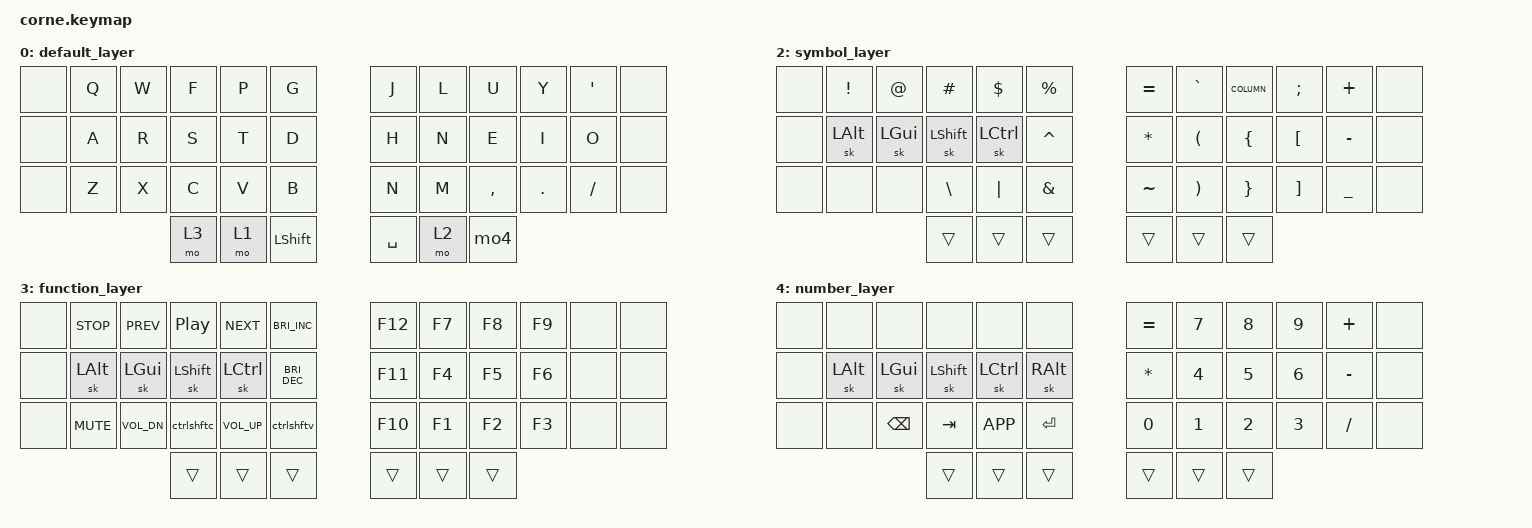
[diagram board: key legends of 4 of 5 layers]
/*
 * Seniply Layout
 * https://stevep99.github.io/seniply/
 */

#include <behaviors.dtsi>
#include <dt-bindings/zmk/keys.h>
#include <dt-bindings/zmk/bt.h>

/ {

    macros {
        bk: bk {
            label = "Backward";
            compatible = "zmk,behavior-macro";
            #binding-cells = <0>;
            bindings
                = <&macro_press &kp LALT>
                , <&macro_tap &kp LEFT>
                , <&macro_release &kp LALT>
                ;
        };
        fw: fw {
            label = "Forward";
            compatible = "zmk,behavior-macro";
            #binding-cells = <0>;
            bindings
                = <&macro_press &kp LALT>
                , <&macro_tap &kp RIGHT>
                , <&macro_release &kp LALT>
                ;
        };
        fnd: fnd {
            label = "Forward";
            compatible = "zmk,behavior-macro";
            #binding-cells = <0>;
            bindings
                = <&macro_press &kp LCTRL>
                , <&macro_tap &kp F>
                , <&macro_release &kp LCTRL>
                ;
        };  
        ctrlz: ctrlz {
            label = "Forward";
            compatible = "zmk,behavior-macro";
            #binding-cells = <0>;
            bindings
                = <&macro_press &kp LCTRL>
                , <&macro_tap &kp Z>
                , <&macro_release &kp LCTRL>
                ;
        };  
        ctrlx: ctrlx {
            label = "Forward";
            compatible = "zmk,behavior-macro";
            #binding-cells = <0>;
            bindings
                = <&macro_press &kp LCTRL>
                , <&macro_tap &kp X>
                , <&macro_release &kp LCTRL>
                ;
        };  
        ctrlc: ctrlc {
            label = "Forward";
            compatible = "zmk,behavior-macro";
            #binding-cells = <0>;
            bindings
                = <&macro_press &kp LCTRL>
                , <&macro_tap &kp C>
                , <&macro_release &kp LCTRL>
                ;
        };   
        ctrlv: ctrlv {
            label = "Forward";
            compatible = "zmk,behavior-macro";
            #binding-cells = <0>;
            bindings
                = <&macro_press &kp LCTRL>
                , <&macro_tap &kp V>
                , <&macro_release &kp LCTRL>
                ;
        };                                               
        ctrlshftc: ctrlshftc {
            label = "Forward";
            compatible = "zmk,behavior-macro";
            #binding-cells = <0>;
            bindings
                = <&macro_press &kp LCTRL>
                , <&macro_press &kp LSHFT>
                , <&macro_tap &kp C>
                , <&macro_release &kp LSHFT>
                , <&macro_release &kp LCTRL>
                ;
        };   
        ctrlshftv: ctrlshftv {
            label = "Forward";
            compatible = "zmk,behavior-macro";
            #binding-cells = <0>;
            bindings
                = <&macro_press &kp LCTRL>
                , <&macro_press &kp LSHFT>
                , <&macro_tap &kp V>
                , <&macro_release &kp LSHFT>
                , <&macro_release &kp LCTRL>
                ;
        };    
    };

    keymap {
        compatible = "zmk,keymap";

        default_layer {
                bindings = <
                    &none   &kp Q       &kp W           &kp F       &kp P           &kp G                               &kp J       &kp L       &kp U       &kp Y       &kp SQT     &none
                    &none   &kp A       &kp R           &kp S       &kp T           &kp D                               &kp H       &kp N       &kp E       &kp I       &kp O       &none   
                    &none   &kp Z       &kp X           &kp C       &kp V           &kp B                               &kp N       &kp M       &kp COMMA   &kp DOT     &kp FSLH    &none   
                                                        &mo 3       &mo 1           &kp LSHFT                           &kp SPACE   &mo 2       &mo4
                >;
        };

        extend_layer {
                bindings = <
                    //&none   &kp ESC     &bk             &fnd        &fw             &kp INS                             &kp PG_UP   &kp HOME    &kp UP      &kp END     &kp CAPS    &none     
                    //&none   &sk LALT    &sk LGUI        &sk LSHFT   &sk LCTRL       &sk RALT                            &kp PG_DOWN &kp LEFT    &kp DOWN    &kp RIGHT   &kp DEL     &none   
                    //&none   &ctrlz      &ctrlx          &ctrlc      &ctrlv          &kp LGUI                            &kp RET     &kp BSPC    &kp TAB     &kp K_APP   &kp PSCRN   &none   
                    //                                    &trans      &trans          &trans                              &trans      &trans      &trans
                >;
        };

        symbol_layer {
                bindings = <
                    &none   &kp EXCL    &kp AT          &kp HASH    &kp DOLLAR      &kp PERCENT                         &kp EQUAL   &kp GRAVE   &kp COLUMN  &kp SEMI    &kp PLUS    &none   
                    &none   &sk LALT    &sk LGUI        &sk LSHFT   &sk LCTRL       &kp CARET                           &kp STAR    &kp LPAR    &kp LBRC    &kp LBKT    &kp MINUS   &none   
                    &none   &none       &none           &kp BSLH    &kp PIPE        &kp AMPS                            &kp TILDE   &kp RPAR    &kp RBRC    &kp RBKT    &kp UNDER   &none   
                                                        &trans      &trans          &trans                              &trans      &trans      &trans
                >;
        };    

        function_layer {
                bindings = <
                    &none   &kp C_STOP  &kp C_PREV      &kp C_PP    &kp C_NEXT      &kp C_BRI_INC                       &kp F12     &kp F7      &kp F8      &kp F9      &none       &none   
                    &none   &sk LALT    &sk LGUI        &sk LSHFT   &sk LCTRL       &kp C_BRI_DEC                       &kp F11     &kp F4      &kp F5      &kp F6      &none       &none   
                    &none   &kp C_MUTE  &kp C_VOL_DN    &ctrlshftc  &kp C_VOL_UP    &ctrlshftv                          &kp F10     &kp F1      &kp F2      &kp F3      &none       &none   
                                                        &trans      &trans          &trans                              &trans      &trans      &trans
                >;
        };

        number_layer { 
                bindings = <
                    &none   &none       &none           &none       &none           &none                               &kp EQUAL   &kp N7      &kp N8      &kp N9      &kp PLUS    &none   
                    &none   &sk LALT    &sk LGUI        &sk LSHFT   &sk LCTRL       &sk RALT                            &kp STAR    &kp N4      &kp N5      &kp N6      &kp MINUS   &none   
                    &none   &none       &kp BSPC        &kp TAB     &kp K_APP       &kp RET                             &kp N0      &kp N1      &kp N2      &kp N3      &kp FSLH    &none   
                                                        &trans      &trans          &trans                              &trans      &trans      &trans
                >;
        };
    };                                 
};
